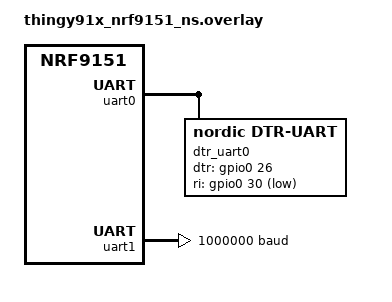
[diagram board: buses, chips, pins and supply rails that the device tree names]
/*
 * Copyright (c) 2024 Nordic Semiconductor ASA
 *
 * SPDX-License-Identifier: LicenseRef-Nordic-5-Clause
 */

/ {
	chosen {
		ncs,sm-uart = &dtr_uart0;
		zephyr,console = &uart1;
	};
};

/* DTR with DK */
&uart0 {
	status = "okay";

	dtr_uart0: dtr-uart {
		compatible = "nordic,dtr-uart";
		dtr-gpios = <&gpio0 26 (GPIO_PULL_UP | GPIO_ACTIVE_HIGH)>; /* button0 */
		ri-gpios = <&gpio0 30 GPIO_ACTIVE_LOW>; /* blue_led */
		status = "okay";
	};
};

&gpio0 {
	status = "okay";
	/* Use PORT event for DTR (26) pin to save power */
	sense-edge-mask = <BIT(26)>;
};

/* Enable UART1 as the shared backend for Zephyr logs and modem traces.
 * Modem traces require 1 000 000 baud. Hardware flow control is not used.
 */
&uart1 {
	status = "okay";
	current-speed = <1000000>;
};
